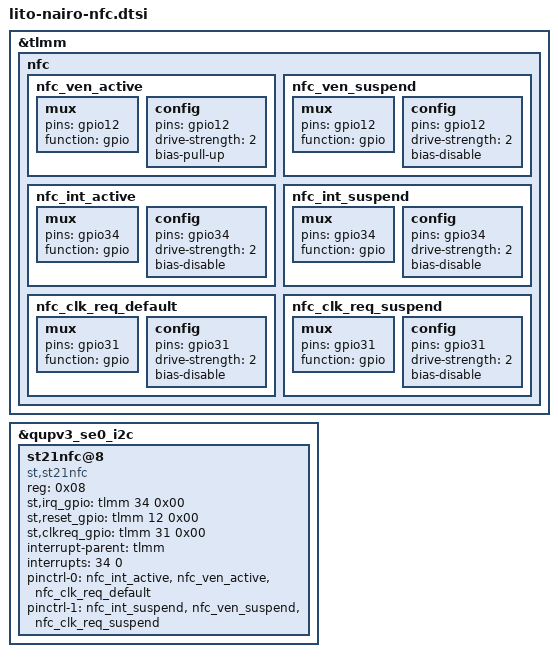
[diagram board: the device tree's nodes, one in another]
&tlmm {
	nfc {
		nfc_ven_active: nfc_ven_active {
			/* active state */
			mux {
				/* 12: Enable */
				pins = "gpio12";
				function = "gpio";
			};

			config {
				pins = "gpio12";
				drive-strength = <2>; /* 2 MA */
				bias-pull-up;
			};
		};

		nfc_ven_suspend: nfc_ven_suspend {
			/* sleep state */
			mux {
				/* 12: Enable */
				pins = "gpio12";
				function = "gpio";
			};

			config {
				pins = "gpio12";
				drive-strength = <2>; /* 2 MA */
				bias-disable;
			};
		};

		nfc_int_active: nfc_int_active {
			/* active state */
			mux {
				/* GPIO 34 NFC Read Interrupt */
				pins = "gpio34";
				function = "gpio";
			};

			config {
				pins = "gpio34";
				drive-strength = <2>; /* 2 MA */
				bias-disable;
			};
		};

		nfc_int_suspend: nfc_int_suspend {
			/* sleep state */
			mux {
				/* GPIO 34 NFC Read Interrupt */
				pins = "gpio34";
				function = "gpio";
			};

			config {
				pins = "gpio34";
				drive-strength = <2>; /* 2 MA */
				bias-disable;
			};
		};

		nfc_clk_req_default: nfc_clk_req_default {
			/* active state */
			mux {
				/* GPIO 31: NFC CLOCK REQUEST */
				pins = "gpio31";
				function = "gpio";
			};

			config {
				pins = "gpio31";
				drive-strength = <2>; /* 2 MA */
				bias-disable;
			};
		};

		nfc_clk_req_suspend: nfc_clk_req_suspend {
			/* sleep state */
			mux {
				/* GPIO 31: NFC CLOCK REQUEST */
				pins = "gpio31";
				function = "gpio";
			};

			config {
				pins = "gpio31";
				drive-strength = <2>; /* 2 MA */
				bias-disable;
			};
		};
	};
};

&qupv3_se0_i2c {
	status = "ok";
	st21nfc@8 {
		compatible = "st,st21nfc";
		status = "ok";
		reg = <0x08>;
		st,irq_gpio = <&tlmm 34 0x00>;
		st,reset_gpio = <&tlmm 12 0x00>;
		st,clkreq_gpio = <&tlmm 31 0x00>;
		interrupt-parent = <&tlmm>;
		interrupts = <34 0>;
		interrupt-names = "nfc_irq";
		pinctrl-names = "nfc_active", "nfc_suspend";
		pinctrl-0 = <&nfc_int_active &nfc_ven_active
				&nfc_clk_req_default>;
		pinctrl-1 = <&nfc_int_suspend &nfc_ven_suspend
				&nfc_clk_req_suspend>;
	};
};

